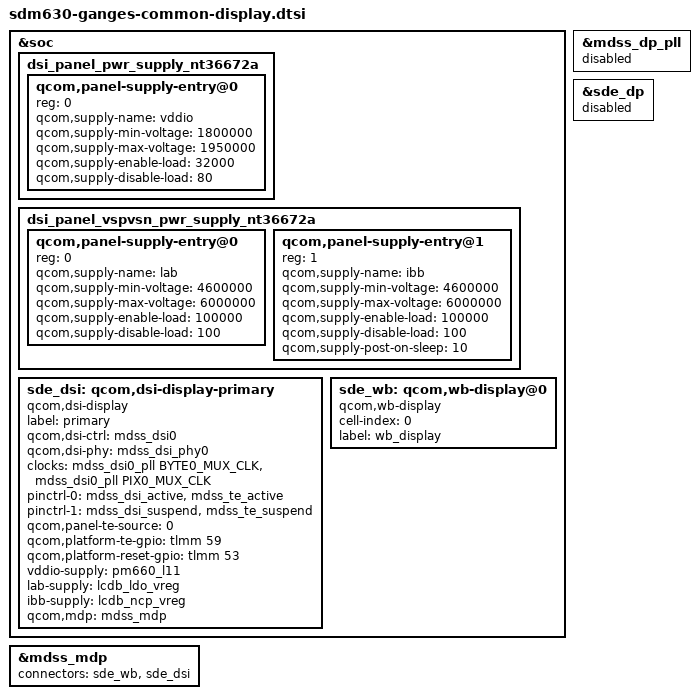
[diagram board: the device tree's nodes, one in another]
// SPDX-License-Identifier: GPL-2.0-only
/*
 * Copyright (c) 2020-2021, The Linux Foundation. All rights reserved.
 */

&soc {
	dsi_panel_pwr_supply_nt36672a: dsi_panel_pwr_supply_nt36672a {
		#address-cells = <1>;
		#size-cells = <0>;

		qcom,panel-supply-entry@0 {
			reg = <0>;
			qcom,supply-name = "vddio";
			qcom,supply-min-voltage = <1800000>;
			qcom,supply-max-voltage = <1950000>;
			qcom,supply-enable-load = <32000>;
			qcom,supply-disable-load = <80>;
		};
	};

	dsi_panel_vspvsn_pwr_supply_nt36672a: dsi_panel_vspvsn_pwr_supply_nt36672a {
		#address-cells = <1>;
		#size-cells = <0>;

		qcom,panel-supply-entry@0 {
			reg = <0>;
			qcom,supply-name = "lab";
			qcom,supply-min-voltage = <4600000>;
			qcom,supply-max-voltage = <6000000>;
			qcom,supply-enable-load = <100000>;
			qcom,supply-disable-load = <100>;
		};

		qcom,panel-supply-entry@1 {
			reg = <1>;
			qcom,supply-name = "ibb";
			qcom,supply-min-voltage = <4600000>;
			qcom,supply-max-voltage = <6000000>;
			qcom,supply-enable-load = <100000>;
			qcom,supply-disable-load = <100>;
			qcom,supply-post-on-sleep = <10>;
		};
	};

	sde_dsi: qcom,dsi-display-primary {
		compatible = "qcom,dsi-display";
		label = "primary";

		qcom,dsi-ctrl = <&mdss_dsi0>;
		qcom,dsi-phy = <&mdss_dsi_phy0>;
		clocks = <&mdss_dsi0_pll BYTE0_MUX_CLK>,
			 <&mdss_dsi0_pll PIX0_MUX_CLK>;
		clock-names = "mux_byte_clk0", "mux_pixel_clk0";

		pinctrl-names = "panel_active", "panel_suspend";
		pinctrl-0 = <&mdss_dsi_active &mdss_te_active>;
		pinctrl-1 = <&mdss_dsi_suspend &mdss_te_suspend>;

		qcom,panel-te-source = <0>;
		qcom,platform-te-gpio = <&tlmm 59 0>;
		qcom,platform-reset-gpio = <&tlmm 53 0>;

		vddio-supply = <&pm660_l11>;
		lab-supply = <&lcdb_ldo_vreg>;
		ibb-supply = <&lcdb_ncp_vreg>;

		qcom,mdp = <&mdss_mdp>;
	};

	sde_wb: qcom,wb-display@0 {
		compatible = "qcom,wb-display";
		cell-index = <0>;
		label = "wb_display";
	};
};

&mdss_mdp {
	//connectors = <&sde_wb &sde_dp>;
	connectors = <&sde_wb &sde_dsi>;
}; 

&mdss_dp_pll {
	status = "disabled";
};

&sde_dp {
	status = "disabled";
};
